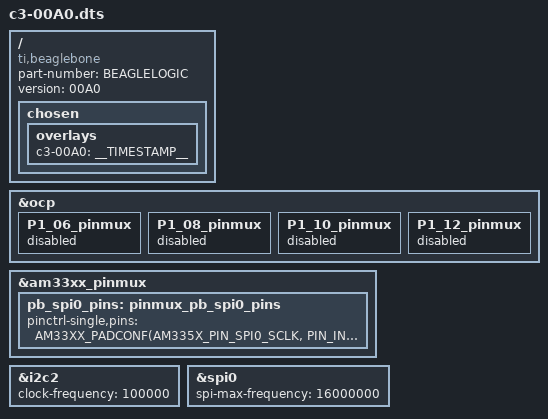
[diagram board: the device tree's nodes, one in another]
/* OreSat C3 overlay */

#include "am33xx.h"

/dts-v1/;
/plugin/;

/ {
  compatible = "ti,beaglebone", "ti,beaglebone-black", "ti,beaglebone-green";
  part-number = "BEAGLELOGIC";
  version = "00A0";

  fragment@0 {
    target-path="/";
    __overlay__ {
      chosen {
          overlays {
            c3-00A0 = __TIMESTAMP__;
	      };
      };
    };
  };

  fragment@1 {
    target = <&ocp>;
    __overlay__ {
      P1_06_pinmux { status = "disabled"; };
      P1_08_pinmux { status = "disabled"; };
      P1_10_pinmux { status = "disabled"; };
      P1_12_pinmux { status = "disabled"; };
    };
  };

  fragment@2 {
    target = <&am33xx_pinmux>;
    __overlay__ {
      pb_spi0_pins: pinmux_pb_spi0_pins  {
        pinctrl-single,pins = <
          AM33XX_PADCONF(AM335X_PIN_SPI0_SCLK, PIN_INPUT, MUX_MODE0)  /* P1_06 spi0_sclk.spi0_sclk */
          AM33XX_PADCONF(AM335X_PIN_SPI0_D0, PIN_INPUT, MUX_MODE0)  /* P1_08 spi0_d0.spi0_d0 */
          AM33XX_PADCONF(AM335X_PIN_SPI0_D1, PIN_INPUT, MUX_MODE0)  /* P1_10 spi0_d1.spi0_d1 */
          AM33XX_PADCONF(AM335X_PIN_SPI0_CS0, PIN_INPUT, MUX_MODE0) /* P1_12 spi0_cs0.spi0_cs0 */
        >;
      };
    };
  };

  fragment@3 {
    target = <&i2c2>;
    __overlay__ {
      status = "okay";

      clock-frequency = <100000>;

      #address-cells = <1>;
      #size-cells = <0>;
    };
  };

  fragment@4 {
    target = <&spi0>;
    status = "okay";
    pinctrl-names = "default";
    pinctrl-0 = <&pb_spi0_pins>;

    __overlay__ {
      spi-max-frequency = <16000000>;

      #address-cells = <1>;
      #size-cells = <0>;
    };
  };
};
